# ddr32ss_EMIF_CTLCFG_0F308000h register map
Vendor: Texas Instruments
Registers are 32-bit, read-write, reset 0x0 unless marked. A register's access mark holds for its fields unless they carry their own. Offsets are as the file gives them; [hi:lo] are bit positions; lines under a group give offsets from that group; {n}, {i} and the like mark numbered series.

## emif_ctlcfg (part 7 of 13)
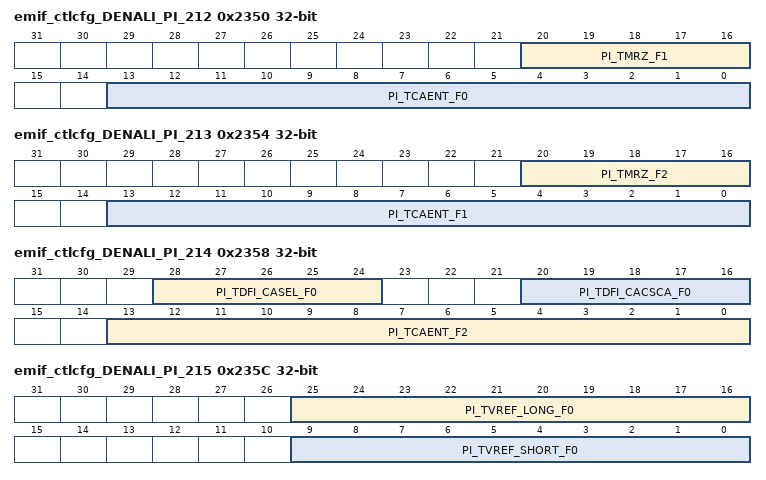
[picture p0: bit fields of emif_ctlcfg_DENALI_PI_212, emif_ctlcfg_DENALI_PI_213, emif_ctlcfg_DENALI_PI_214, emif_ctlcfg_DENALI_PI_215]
0x2350 emif_ctlcfg_DENALI_PI_212
  [20:16] PI_TMRZ_F1 — Defines the delay between a MRW CA exit command and the DQ tristate in memory clocks for frequency set 1. Reset Source: ctl_amod_g_rst_n
  [13:0] PI_TCAENT_F0 — Defines the DRAM tCAENT term, in memory clocks for frequency set 0. Reset Source: ctl_amod_g_rst_n
0x2354 emif_ctlcfg_DENALI_PI_213
  [20:16] PI_TMRZ_F2 — Defines the delay between a MRW CA exit command and the DQ tristate in memory clocks for frequency set 2. Reset Source: ctl_amod_g_rst_n
  [13:0] PI_TCAENT_F1 — Defines the DRAM tCAENT term, in memory clocks for frequency set 1. Reset Source: ctl_amod_g_rst_n
0x2358 emif_ctlcfg_DENALI_PI_214
  [28:24] PI_TDFI_CASEL_F0 — Defines the DFI tcalvl_ca_sel timing parameter, the width of dfi_calvl_ca_sel in PHY DFI clock cycles for frequency set 0. Reset Source: ctl_amod_g_rst_n
  [20:16] PI_TDFI_CACSCA_F0 — Defines the DFI tcalvl_cs_ca timing parameter, the number of PHY DFI clocks from the assertion of dfi_calvl_ca_sel to the assertion of dfi_cs for frequency set 0. Reset Source: ctl_amod_g_rst_n
  [13:0] PI_TCAENT_F2 — Defines the DRAM tCAENT term, in memory clocks for frequency set 2. Reset Source: ctl_amod_g_rst_n
0x235C emif_ctlcfg_DENALI_PI_215
  [25:16] PI_TVREF_LONG_F0 — Defines the delay in PI clock cycles between the dfi_calvl_strobe to the next command if the pi_calvl_vref_stepsize parameter gt 1 for frequency set 0. Reset Source: ctl_amod_g_rst_n
  [9:0] PI_TVREF_SHORT_F0 — Defines the delay in PI clock cycles between the dfi_calvl_strobe to the next command if the pi_calvl_vref_stepsize parameter = 1 for frequency set 0. Reset Source: ctl_amod_g_rst_n
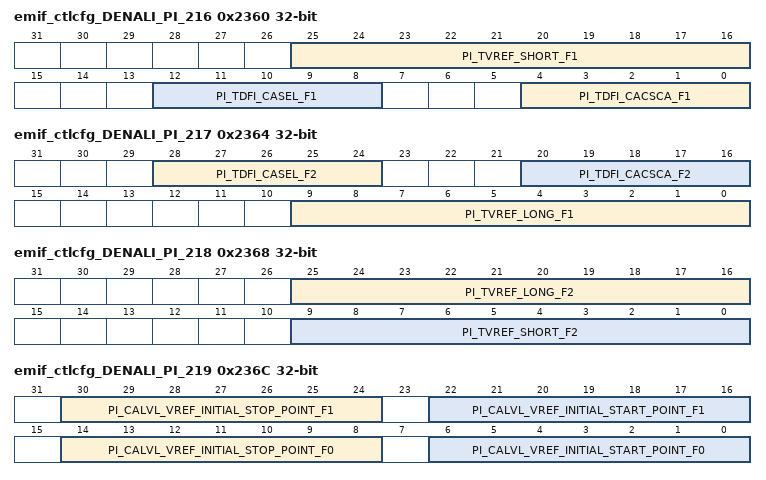
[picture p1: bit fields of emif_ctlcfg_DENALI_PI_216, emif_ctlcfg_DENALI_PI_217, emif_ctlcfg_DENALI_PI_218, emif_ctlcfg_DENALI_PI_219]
0x2360 emif_ctlcfg_DENALI_PI_216
  [25:16] PI_TVREF_SHORT_F1 — Defines the delay in PI clock cycles between the dfi_calvl_strobe to the next command if the pi_calvl_vref_stepsize parameter = 1 for frequency set 1. Reset Source: ctl_amod_g_rst_n
  [12:8] PI_TDFI_CASEL_F1 — Defines the DFI tcalvl_ca_sel timing parameter, the width of dfi_calvl_ca_sel in PHY DFI clock cycles for frequency set 1. Reset Source: ctl_amod_g_rst_n
  [4:0] PI_TDFI_CACSCA_F1 — Defines the DFI tcalvl_cs_ca timing parameter, the number of PHY DFI clocks from the assertion of dfi_calvl_ca_sel to the assertion of dfi_cs for frequency set 1. Reset Source: ctl_amod_g_rst_n
0x2364 emif_ctlcfg_DENALI_PI_217
  [28:24] PI_TDFI_CASEL_F2 — Defines the DFI tcalvl_ca_sel timing parameter, the width of dfi_calvl_ca_sel in PHY DFI clock cycles for frequency set 2. Reset Source: ctl_amod_g_rst_n
  [20:16] PI_TDFI_CACSCA_F2 — Defines the DFI tcalvl_cs_ca timing parameter, the number of PHY DFI clocks from the assertion of dfi_calvl_ca_sel to the assertion of dfi_cs for frequency set 2. Reset Source: ctl_amod_g_rst_n
  [9:0] PI_TVREF_LONG_F1 — Defines the delay in PI clock cycles between the dfi_calvl_strobe to the next command if the pi_calvl_vref_stepsize parameter gt 1 for frequency set 1. Reset Source: ctl_amod_g_rst_n
0x2368 emif_ctlcfg_DENALI_PI_218
  [25:16] PI_TVREF_LONG_F2 — Defines the delay in PI clock cycles between the dfi_calvl_strobe to the next command if the pi_calvl_vref_stepsize parameter gt 1 for frequency set 2. Reset Source: ctl_amod_g_rst_n
  [9:0] PI_TVREF_SHORT_F2 — Defines the delay in PI clock cycles between the dfi_calvl_strobe to the next command if the pi_calvl_vref_stepsize parameter = 1 for frequency set 2. Reset Source: ctl_amod_g_rst_n
0x236C emif_ctlcfg_DENALI_PI_219
  [30:24] PI_CALVL_VREF_INITIAL_STOP_POINT_F1 — The end point of initial training for the Vref[ca] training for frequency set 1 { vrefca_range, vref_ca_setting[5:0]}. Reset Source: ctl_amod_g_rst_n
  [22:16] PI_CALVL_VREF_INITIAL_START_POINT_F1 — The start point of initial training for the Vref[ca] training for frequency set 1 { vrefca_range, vref_ca_setting[5:0]}. Reset Source: ctl_amod_g_rst_n
  [14:8] PI_CALVL_VREF_INITIAL_STOP_POINT_F0 — The end point of initial training for the Vref[ca] training for frequency set 0 { vrefca_range, vref_ca_setting[5:0]}. Reset Source: ctl_amod_g_rst_n
  [6:0] PI_CALVL_VREF_INITIAL_START_POINT_F0 — The start point of initial training for the Vref[ca] training for frequency set 0 { vrefca_range, vref_ca_setting[5:0]}. Reset Source: ctl_amod_g_rst_n
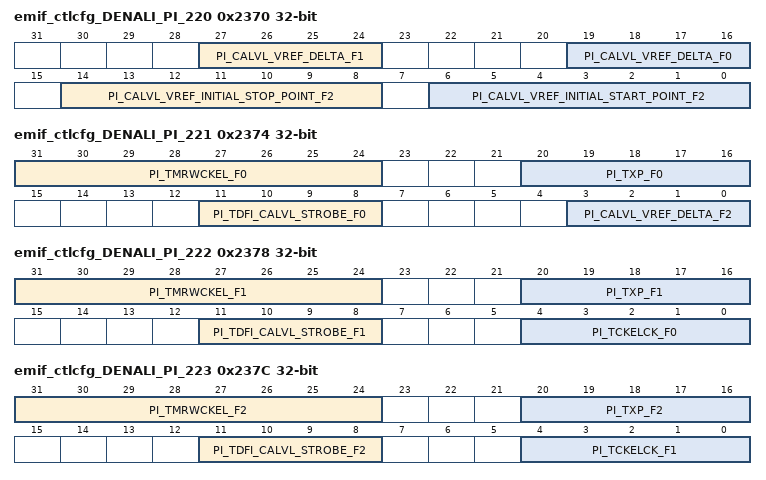
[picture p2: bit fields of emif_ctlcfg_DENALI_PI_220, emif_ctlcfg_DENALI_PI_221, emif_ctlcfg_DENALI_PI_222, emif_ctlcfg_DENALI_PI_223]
0x2370 emif_ctlcfg_DENALI_PI_220
  [27:24] PI_CALVL_VREF_DELTA_F1 — The delta fro the current CA vref for non-initial CA training for frequency set 1. Reset Source: ctl_amod_g_rst_n
  [19:16] PI_CALVL_VREF_DELTA_F0 — The delta fro the current CA vref for non-initial CA training for frequency set 0. Reset Source: ctl_amod_g_rst_n
  [14:8] PI_CALVL_VREF_INITIAL_STOP_POINT_F2 — The end point of initial training for the Vref[ca] training for frequency set 2 { vrefca_range, vref_ca_setting[5:0]}. Reset Source: ctl_amod_g_rst_n
  [6:0] PI_CALVL_VREF_INITIAL_START_POINT_F2 — The start point of initial training for the Vref[ca] training for frequency set 2 { vrefca_range, vref_ca_setting[5:0]}. Reset Source: ctl_amod_g_rst_n
0x2374 emif_ctlcfg_DENALI_PI_221
  [31:24] PI_TMRWCKEL_F0 — Valid Clock and CS Requirement before CKE deassert after MRW Command for frequency set 0. Reset Source: ctl_amod_g_rst_n
  [20:16] PI_TXP_F0 — CKE assert to next valid command delay for frequency set 0. Reset Source: ctl_amod_g_rst_n
  [11:8] PI_TDFI_CALVL_STROBE_F0 — Minimum number of DFI PHY clocks from dfi_calvl_data to dfi_calvl_strobe mode for frequency set 0. Reset Source: ctl_amod_g_rst_n
  [3:0] PI_CALVL_VREF_DELTA_F2 — The delta fro the current CA vref for non-initial CA training for frequency set 2. Reset Source: ctl_amod_g_rst_n
0x2378 emif_ctlcfg_DENALI_PI_222
  [31:24] PI_TMRWCKEL_F1 — Valid Clock and CS Requirement before CKE deassert after MRW Command for frequency set 1. Reset Source: ctl_amod_g_rst_n
  [20:16] PI_TXP_F1 — CKE assert to next valid command delay for frequency set 1. Reset Source: ctl_amod_g_rst_n
  [11:8] PI_TDFI_CALVL_STROBE_F1 — Minimum number of DFI PHY clocks from dfi_calvl_data to dfi_calvl_strobe mode for frequency set 1. Reset Source: ctl_amod_g_rst_n
  [4:0] PI_TCKELCK_F0 — Valid Clock Requirement after CKE deassert for frequency set 0. Reset Source: ctl_amod_g_rst_n
0x237C emif_ctlcfg_DENALI_PI_223
  [31:24] PI_TMRWCKEL_F2 — Valid Clock and CS Requirement before CKE deassert after MRW Command for frequency set 2. Reset Source: ctl_amod_g_rst_n
  [20:16] PI_TXP_F2 — CKE assert to next valid command delay for frequency set 2. Reset Source: ctl_amod_g_rst_n
  [11:8] PI_TDFI_CALVL_STROBE_F2 — Minimum number of DFI PHY clocks from dfi_calvl_data to dfi_calvl_strobe mode for frequency set 2. Reset Source: ctl_amod_g_rst_n
  [4:0] PI_TCKELCK_F1 — Valid Clock Requirement after CKE deassert for frequency set 1. Reset Source: ctl_amod_g_rst_n
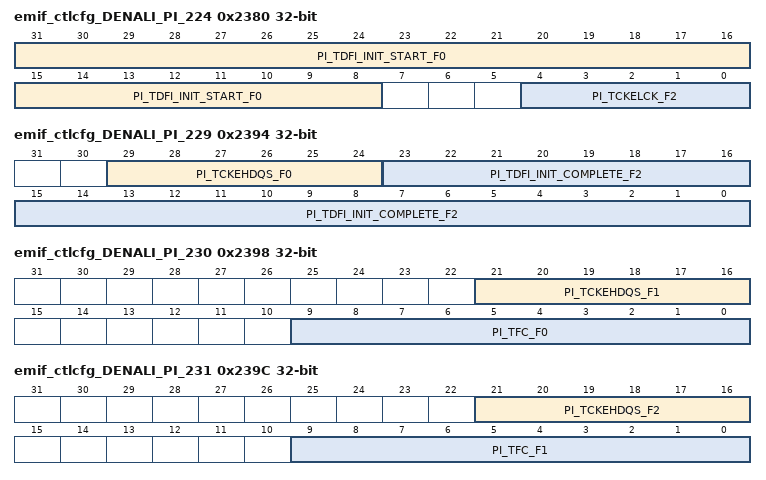
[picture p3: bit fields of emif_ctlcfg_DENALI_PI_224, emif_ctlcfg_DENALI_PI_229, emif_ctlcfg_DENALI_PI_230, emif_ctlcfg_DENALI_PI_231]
0x2380 emif_ctlcfg_DENALI_PI_224
  [31:8] PI_TDFI_INIT_START_F0 — Defines the DFI tINIT_START timing parameter [in DFI clocks] for frequency set 0, the maximum number of cycles between a dfi_init_start assertion and a dfi_init_complete de-assertion from the PHY. Reset Source: ctl_amod_g_rst_n
  [4:0] PI_TCKELCK_F2 — Valid Clock Requirement after CKE deassert for frequency set 2. Reset Source: ctl_amod_g_rst_n
0x2384 emif_ctlcfg_DENALI_PI_225
  [23:0] PI_TDFI_INIT_COMPLETE_F0 — Defines the DFI tINIT_COMPLETE timing parameter [in DFI clocks] for frequency set 0, the maximum cycles between a dfi_init_start de-assertion and a dfi_init_complete assertion from the PHY. Reset Source: ctl_amod_g_rst_n
0x2388 emif_ctlcfg_DENALI_PI_226
  [23:0] PI_TDFI_INIT_START_F1 — Defines the DFI tINIT_START timing parameter [in DFI clocks] for frequency set 1, the maximum number of cycles between a dfi_init_start assertion and a dfi_init_complete de-assertion from the PHY. Reset Source: ctl_amod_g_rst_n
0x238C emif_ctlcfg_DENALI_PI_227
  [23:0] PI_TDFI_INIT_COMPLETE_F1 — Defines the DFI tINIT_COMPLETE timing parameter [in DFI clocks] for frequency set 1, the maximum cycles between a dfi_init_start de-assertion and a dfi_init_complete assertion from the PHY. Reset Source: ctl_amod_g_rst_n
0x2390 emif_ctlcfg_DENALI_PI_228
  [23:0] PI_TDFI_INIT_START_F2 — Defines the DFI tINIT_START timing parameter [in DFI clocks] for frequency set 2, the maximum number of cycles between a dfi_init_start assertion and a dfi_init_complete de-assertion from the PHY. Reset Source: ctl_amod_g_rst_n
0x2394 emif_ctlcfg_DENALI_PI_229
  [29:24] PI_TCKEHDQS_F0 — The DRAM timing tCKEHDQS, minimum delay from CKE high to strobe high impedance for frequency set 0. Reset Source: ctl_amod_g_rst_n
  [23:0] PI_TDFI_INIT_COMPLETE_F2 — Defines the DFI tINIT_COMPLETE timing parameter [in DFI clocks] for frequency set 2, the maximum cycles between a dfi_init_start de-assertion and a dfi_init_complete assertion from the PHY. Reset Source: ctl_amod_g_rst_n
0x2398 emif_ctlcfg_DENALI_PI_230
  [21:16] PI_TCKEHDQS_F1 — The DRAM timing tCKEHDQS, minimum delay from CKE high to strobe high impedance for frequency set 1. Reset Source: ctl_amod_g_rst_n
  [9:0] PI_TFC_F0 — The delay in PHY clock cycles from setting MR13.OP7 to any valid command for frequency set 0. Reset Source: ctl_amod_g_rst_n
0x239C emif_ctlcfg_DENALI_PI_231
  [21:16] PI_TCKEHDQS_F2 — The DRAM timing tCKEHDQS, minimum delay from CKE high to strobe high impedance for frequency set 2. Reset Source: ctl_amod_g_rst_n
  [9:0] PI_TFC_F1 — The delay in PHY clock cycles from setting MR13.OP7 to any valid command for frequency set 1. Reset Source: ctl_amod_g_rst_n
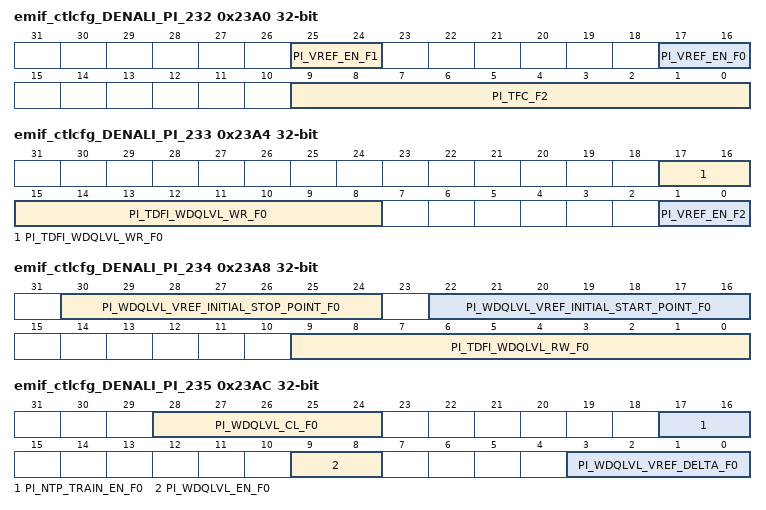
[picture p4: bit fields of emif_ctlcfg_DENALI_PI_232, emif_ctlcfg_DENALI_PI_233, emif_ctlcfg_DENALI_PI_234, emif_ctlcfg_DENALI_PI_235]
0x23A0 emif_ctlcfg_DENALI_PI_232
  [25:24] PI_VREF_EN_F1 — Enable VREF training during power-up initialization for frequency set 1. Bit[1] represents the support when non-initialization. Bit[0]represents the support when initialization. Set to 1 to enable. Reset Source: ctl_amod_g_rst_n
  [17:16] PI_VREF_EN_F0 — Enable VREF training during power-up initialization for frequency set 0. Bit[1] represents the support when non-initialization. Bit[0]represents the support when initialization. Set to 1 to enable. Reset Source: ctl_amod_g_rst_n
  [9:0] PI_TFC_F2 — The delay in PHY clock cycles from setting MR13.OP7 to any valid command for frequency set 2. Reset Source: ctl_amod_g_rst_n
0x23A4 emif_ctlcfg_DENALI_PI_233
  [17:8] PI_TDFI_WDQLVL_WR_F0 — Switch time from write to read for frequency set 0. Reset Source: ctl_amod_g_rst_n
  [1:0] PI_VREF_EN_F2 — Enable VREF training during power-up initialization for frequency set 2. Bit[1] represents the support when non-initialization. Bit[0]represents the support when initialization. Set to 1 to enable. Reset Source: ctl_amod_g_rst_n
0x23A8 emif_ctlcfg_DENALI_PI_234
  [30:24] PI_WDQLVL_VREF_INITIAL_STOP_POINT_F0 — Write DQ training vref initial training stop value for frequency set 0. Reset Source: ctl_amod_g_rst_n
  [22:16] PI_WDQLVL_VREF_INITIAL_START_POINT_F0 — Write DQ training vref initial training start value for frequency set 0. Reset Source: ctl_amod_g_rst_n
  [9:0] PI_TDFI_WDQLVL_RW_F0 — Switch time from read to write for frequency set 0. Reset Source: ctl_amod_g_rst_n
0x23AC emif_ctlcfg_DENALI_PI_235
  [28:24] PI_WDQLVL_CL_F0 — CL when the Read DBI disabled while doing WDQ training for frequency set 0. Reset Source: ctl_amod_g_rst_n
  [17:16] PI_NTP_TRAIN_EN_F0 — Indicates whether the no topology WDQ training is enabled. Bit[1] represents the support when non-initialization. Bit[0]represents the support when initialization. Reset Source: ctl_amod_g_rst_n
  [9:8] PI_WDQLVL_EN_F0 — Indicates if Write DQ leveling is enabled for frequency set 0. Bit[1] represents the support when non-initialization. Bit[0]represents the support when initialization. Reset Source: ctl_amod_g_rst_n
  [3:0] PI_WDQLVL_VREF_DELTA_F0 — The delta from the current Write DQ vref adjustment for non-initial wdq training for frequency set 0. Reset Source: ctl_amod_g_rst_n
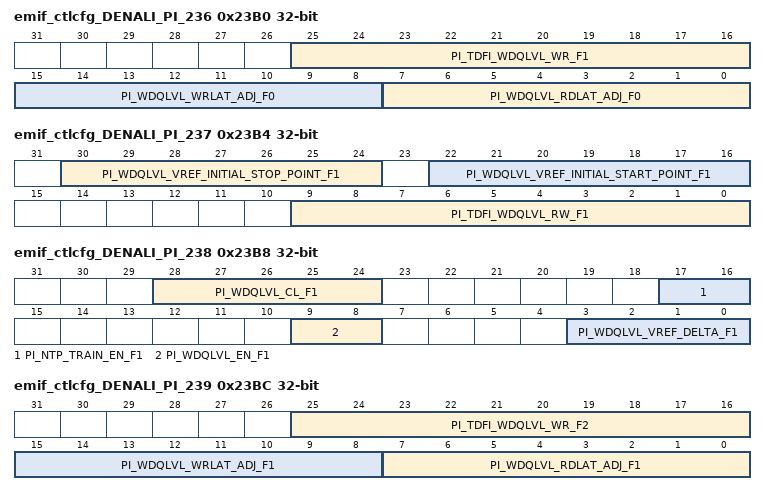
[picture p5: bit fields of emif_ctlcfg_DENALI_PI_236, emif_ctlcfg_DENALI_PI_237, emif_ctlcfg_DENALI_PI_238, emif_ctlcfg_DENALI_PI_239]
0x23B0 emif_ctlcfg_DENALI_PI_236
  [25:16] PI_TDFI_WDQLVL_WR_F1 — Switch time from write to read for frequency set 1. Reset Source: ctl_amod_g_rst_n
  [15:8] PI_WDQLVL_WRLAT_ADJ_F0 — Adjusted Tdfi_wrdata_en value for PHY read timing when read dbi disabled for frequency set 0, used for WDQ training. Reset Source: ctl_amod_g_rst_n
  [7:0] PI_WDQLVL_RDLAT_ADJ_F0 — Adjusted Tdfi_rddata_en value for PHY read timing when read dbi disabled for frequency set 0, used for WDQ training. Reset Source: ctl_amod_g_rst_n
0x23B4 emif_ctlcfg_DENALI_PI_237
  [30:24] PI_WDQLVL_VREF_INITIAL_STOP_POINT_F1 — Write DQ training vref initial training stop value for frequency set 1. Reset Source: ctl_amod_g_rst_n
  [22:16] PI_WDQLVL_VREF_INITIAL_START_POINT_F1 — Write DQ training vref initial training start value for frequency set 1. Reset Source: ctl_amod_g_rst_n
  [9:0] PI_TDFI_WDQLVL_RW_F1 — Switch time from read to write for frequency set 1. Reset Source: ctl_amod_g_rst_n
0x23B8 emif_ctlcfg_DENALI_PI_238
  [28:24] PI_WDQLVL_CL_F1 — CL when the Read DBI disabled while doing WDQ training for frequency set 1. Reset Source: ctl_amod_g_rst_n
  [17:16] PI_NTP_TRAIN_EN_F1 — Indicates whether the no topology WDQ training is enabled. Bit[1] represents the support when non-initialization. Bit[0]represents the support when initialization. Reset Source: ctl_amod_g_rst_n
  [9:8] PI_WDQLVL_EN_F1 — Indicates if Write DQ leveling is enabled for frequency set 1. Bit[1] represents the support when non-initialization. Bit[0]represents the support when initialization. Reset Source: ctl_amod_g_rst_n
  [3:0] PI_WDQLVL_VREF_DELTA_F1 — The delta from the current Write DQ vref adjustment for non-initial wdq training for frequency set 1. Reset Source: ctl_amod_g_rst_n
0x23BC emif_ctlcfg_DENALI_PI_239
  [25:16] PI_TDFI_WDQLVL_WR_F2 — Switch time from write to read for frequency set 2. Reset Source: ctl_amod_g_rst_n
  [15:8] PI_WDQLVL_WRLAT_ADJ_F1 — Adjusted Tdfi_wrdata_en value for PHY read timing when read dbi disabled for frequency set 1, used for WDQ training. Reset Source: ctl_amod_g_rst_n
  [7:0] PI_WDQLVL_RDLAT_ADJ_F1 — Adjusted Tdfi_rddata_en value for PHY read timing when read dbi disabled for frequency set 1, used for WDQ training. Reset Source: ctl_amod_g_rst_n
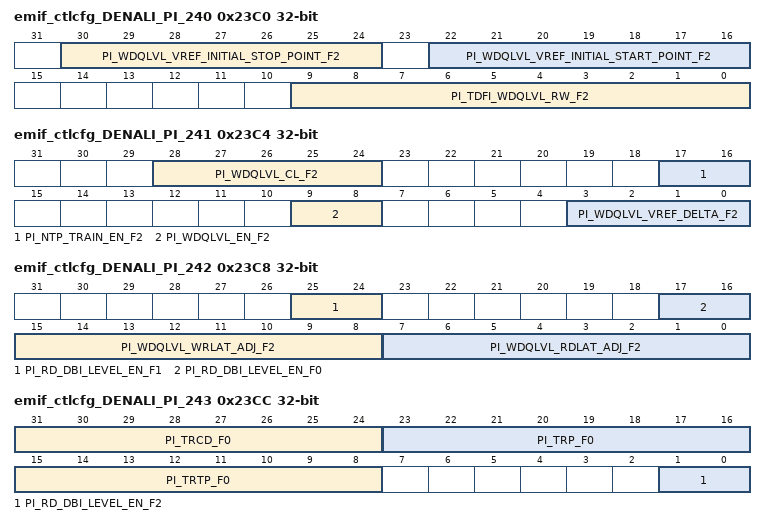
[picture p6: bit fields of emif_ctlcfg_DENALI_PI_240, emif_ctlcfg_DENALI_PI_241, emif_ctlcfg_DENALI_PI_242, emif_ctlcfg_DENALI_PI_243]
0x23C0 emif_ctlcfg_DENALI_PI_240
  [30:24] PI_WDQLVL_VREF_INITIAL_STOP_POINT_F2 — Write DQ training vref initial training stop value for frequency set 2. Reset Source: ctl_amod_g_rst_n
  [22:16] PI_WDQLVL_VREF_INITIAL_START_POINT_F2 — Write DQ training vref initial training start value for frequency set 2. Reset Source: ctl_amod_g_rst_n
  [9:0] PI_TDFI_WDQLVL_RW_F2 — Switch time from read to write for frequency set 2. Reset Source: ctl_amod_g_rst_n
0x23C4 emif_ctlcfg_DENALI_PI_241
  [28:24] PI_WDQLVL_CL_F2 — CL when the Read DBI disabled while doing WDQ training for frequency set 2. Reset Source: ctl_amod_g_rst_n
  [17:16] PI_NTP_TRAIN_EN_F2 — Indicates whether the no topology WDQ training is enabled. Bit[1] represents the support when non-initialization. Bit[0]represents the support when initialization. Reset Source: ctl_amod_g_rst_n
  [9:8] PI_WDQLVL_EN_F2 — Indicates if Write DQ leveling is enabled for frequency set 2. Bit[1] represents the support when non-initialization. Bit[0]represents the support when initialization. Reset Source: ctl_amod_g_rst_n
  [3:0] PI_WDQLVL_VREF_DELTA_F2 — The delta from the current Write DQ vref adjustment for non-initial wdq training for frequency set 2. Reset Source: ctl_amod_g_rst_n
0x23C8 emif_ctlcfg_DENALI_PI_242
  [25:24] PI_RD_DBI_LEVEL_EN_F1 — Read DBI leveling enable, only can be enabled when READ DBI supported for DDR4, and PI_WDQLVL_EN or PI_RDLVL_EN configured by 1 for frequency set 1. Bit[1] represents the support when non-initialization. Bit[0]represents the support when initialization. Reset Source: ctl_amod_g_rst_n
  [17:16] PI_RD_DBI_LEVEL_EN_F0 — Read DBI leveling enable, only can be enabled when READ DBI supported for DDR4, and PI_WDQLVL_EN or PI_RDLVL_EN configured by 1 for frequency set 0. Bit[1] represents the support when non-initialization. Bit[0]represents the support when initialization. Reset Source: ctl_amod_g_rst_n
  [15:8] PI_WDQLVL_WRLAT_ADJ_F2 — Adjusted Tdfi_wrdata_en value for PHY read timing when read dbi disabled for frequency set 2, used for WDQ training. Reset Source: ctl_amod_g_rst_n
  [7:0] PI_WDQLVL_RDLAT_ADJ_F2 — Adjusted Tdfi_rddata_en value for PHY read timing when read dbi disabled for frequency set 2, used for WDQ training. Reset Source: ctl_amod_g_rst_n
0x23CC emif_ctlcfg_DENALI_PI_243
  [31:24] PI_TRCD_F0 — DRAM tRCD value in cycles for frequency set 0. Reset Source: ctl_amod_g_rst_n
  [23:16] PI_TRP_F0 — DRAM tRP value in cycles for frequency set 0. Reset Source: ctl_amod_g_rst_n
  [15:8] PI_TRTP_F0 — DRAM tRTP value in cycles for frequency set 0. Reset Source: ctl_amod_g_rst_n
  [1:0] PI_RD_DBI_LEVEL_EN_F2 — Read DBI leveling enable, only can be enabled when READ DBI supported for DDR4, and PI_WDQLVL_EN or PI_RDLVL_EN configured by 1 for frequency set 2. Bit[1] represents the support when non-initialization. Bit[0]represents the support when initialization. Reset Source: ctl_amod_g_rst_n
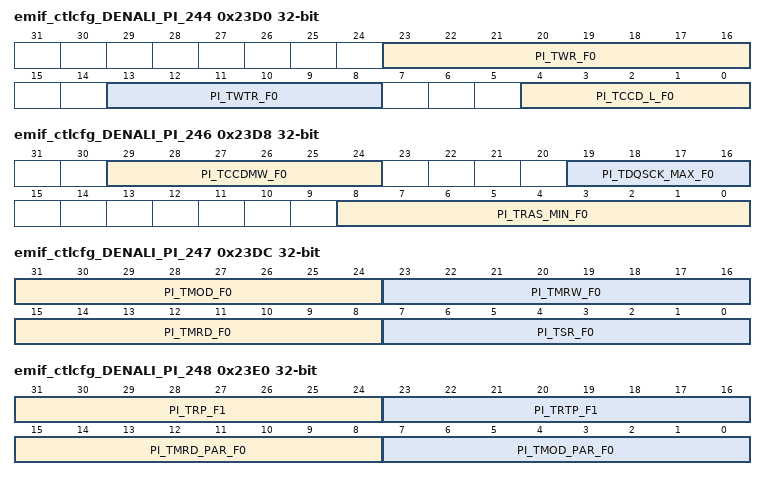
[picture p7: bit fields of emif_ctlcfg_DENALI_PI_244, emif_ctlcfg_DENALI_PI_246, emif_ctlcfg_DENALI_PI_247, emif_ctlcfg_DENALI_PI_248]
0x23D0 emif_ctlcfg_DENALI_PI_244
  [23:16] PI_TWR_F0 — DRAM tWR value in cycles for frequency set 0. Reset Source: ctl_amod_g_rst_n
  [13:8] PI_TWTR_F0 — DRAM tWTR value in cycles for frequency set 0. Reset Source: ctl_amod_g_rst_n
  [4:0] PI_TCCD_L_F0 — DRAM CAS-to_CAS value within the same bank group in cycles for frequency set 0. Reset Source: ctl_amod_g_rst_n
0x23D4 emif_ctlcfg_DENALI_PI_245
  [19:0] PI_TRAS_MAX_F0 — DRAM tRAS_MAX value in cycles for frequency set 0. Reset Source: ctl_amod_g_rst_n
0x23D8 emif_ctlcfg_DENALI_PI_246
  [29:24] PI_TCCDMW_F0 — LPDDR4 DRAM tCCDMW in cycles for frequency set 0. Reset Source: ctl_amod_g_rst_n
  [19:16] PI_TDQSCK_MAX_F0 — Additional delay needed for tDQSCK for frequency set 0. Reset Source: ctl_amod_g_rst_n
  [8:0] PI_TRAS_MIN_F0 — DRAM tRAS_MIN value in cycles for frequency set 0. Reset Source: ctl_amod_g_rst_n
0x23DC emif_ctlcfg_DENALI_PI_247
  [31:24] PI_TMOD_F0 — DRAM tMOD value in cycles for frequency set 0. Reset Source: ctl_amod_g_rst_n
  [23:16] PI_TMRW_F0 — DRAM tMRW value in cycles for frequency set 0. Reset Source: ctl_amod_g_rst_n
  [15:8] PI_TMRD_F0 — DRAM tMRD value in cycles for frequency set 0. Reset Source: ctl_amod_g_rst_n
  [7:0] PI_TSR_F0 — Min cycles from sref entry to sref exit for frequency set 0. Reset Source: ctl_amod_g_rst_n
0x23E0 emif_ctlcfg_DENALI_PI_248
  [31:24] PI_TRP_F1 — DRAM tRP value in cycles for frequency set 1. Reset Source: ctl_amod_g_rst_n
  [23:16] PI_TRTP_F1 — DRAM tRTP value in cycles for frequency set 1. Reset Source: ctl_amod_g_rst_n
  [15:8] PI_TMRD_PAR_F0 — DRAM tMRD value when CA parity is enabled in cycles for frequency set 0. Reset Source: ctl_amod_g_rst_n
  [7:0] PI_TMOD_PAR_F0 — DRAM tMOD value when CA parity is enabled in cycles for frequency set 0. Reset Source: ctl_amod_g_rst_n
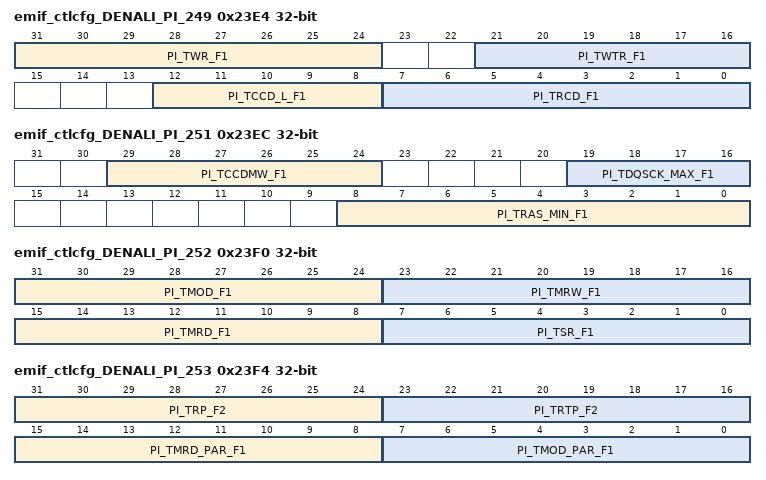
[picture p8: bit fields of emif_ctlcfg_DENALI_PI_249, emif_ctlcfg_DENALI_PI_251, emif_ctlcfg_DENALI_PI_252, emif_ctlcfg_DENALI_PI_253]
0x23E4 emif_ctlcfg_DENALI_PI_249
  [31:24] PI_TWR_F1 — DRAM tWR value in cycles for frequency set 1. Reset Source: ctl_amod_g_rst_n
  [21:16] PI_TWTR_F1 — DRAM tWTR value in cycles for frequency set 1. Reset Source: ctl_amod_g_rst_n
  [12:8] PI_TCCD_L_F1 — DRAM CAS-to_CAS value within the same bank group in cycles for frequency set 1. Reset Source: ctl_amod_g_rst_n
  [7:0] PI_TRCD_F1 — DRAM tRCD value in cycles for frequency set 1. Reset Source: ctl_amod_g_rst_n
0x23E8 emif_ctlcfg_DENALI_PI_250
  [19:0] PI_TRAS_MAX_F1 — DRAM tRAS_MAX value in cycles for frequency set 1. Reset Source: ctl_amod_g_rst_n
0x23EC emif_ctlcfg_DENALI_PI_251
  [29:24] PI_TCCDMW_F1 — LPDDR4 DRAM tCCDMW in cycles for frequency set 1. Reset Source: ctl_amod_g_rst_n
  [19:16] PI_TDQSCK_MAX_F1 — Additional delay needed for tDQSCK for frequency set 1. Reset Source: ctl_amod_g_rst_n
  [8:0] PI_TRAS_MIN_F1 — DRAM tRAS_MIN value in cycles for frequency set 1. Reset Source: ctl_amod_g_rst_n
0x23F0 emif_ctlcfg_DENALI_PI_252
  [31:24] PI_TMOD_F1 — DRAM tMOD value in cycles for frequency set 1. Reset Source: ctl_amod_g_rst_n
  [23:16] PI_TMRW_F1 — DRAM tMRW value in cycles for frequency set 1. Reset Source: ctl_amod_g_rst_n
  [15:8] PI_TMRD_F1 — DRAM tMRD value in cycles for frequency set 1. Reset Source: ctl_amod_g_rst_n
  [7:0] PI_TSR_F1 — Min cycles from sref entry to sref exit for frequency set 1. Reset Source: ctl_amod_g_rst_n
0x23F4 emif_ctlcfg_DENALI_PI_253
  [31:24] PI_TRP_F2 — DRAM tRP value in cycles for frequency set 2. Reset Source: ctl_amod_g_rst_n
  [23:16] PI_TRTP_F2 — DRAM tRTP value in cycles for frequency set 2. Reset Source: ctl_amod_g_rst_n
  [15:8] PI_TMRD_PAR_F1 — DRAM tMRD value when CA parity is enabled in cycles for frequency set 1. Reset Source: ctl_amod_g_rst_n
  [7:0] PI_TMOD_PAR_F1 — DRAM tMOD value when CA parity is enabled in cycles for frequency set 1. Reset Source: ctl_amod_g_rst_n
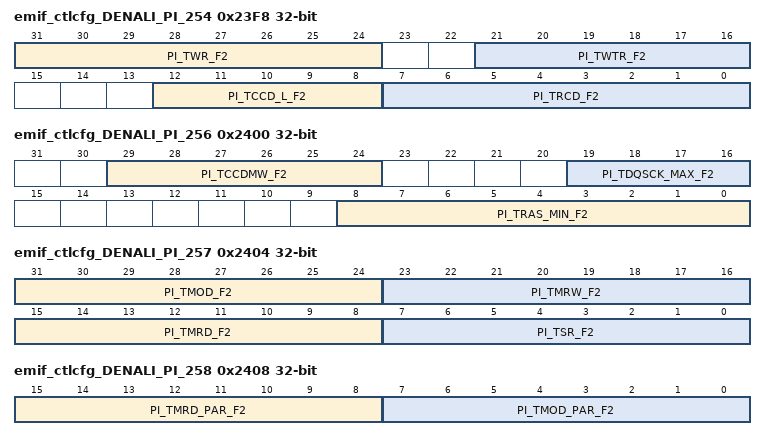
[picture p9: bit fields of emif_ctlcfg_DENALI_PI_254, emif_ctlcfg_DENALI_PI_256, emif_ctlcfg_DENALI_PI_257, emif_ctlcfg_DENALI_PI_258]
0x23F8 emif_ctlcfg_DENALI_PI_254
  [31:24] PI_TWR_F2 — DRAM tWR value in cycles for frequency set 2. Reset Source: ctl_amod_g_rst_n
  [21:16] PI_TWTR_F2 — DRAM tWTR value in cycles for frequency set 2. Reset Source: ctl_amod_g_rst_n
  [12:8] PI_TCCD_L_F2 — DRAM CAS-to_CAS value within the same bank group in cycles for frequency set 2. Reset Source: ctl_amod_g_rst_n
  [7:0] PI_TRCD_F2 — DRAM tRCD value in cycles for frequency set 2. Reset Source: ctl_amod_g_rst_n
0x23FC emif_ctlcfg_DENALI_PI_255
  [19:0] PI_TRAS_MAX_F2 — DRAM tRAS_MAX value in cycles for frequency set 2. Reset Source: ctl_amod_g_rst_n
0x2400 emif_ctlcfg_DENALI_PI_256
  [29:24] PI_TCCDMW_F2 — LPDDR4 DRAM tCCDMW in cycles for frequency set 2. Reset Source: ctl_amod_g_rst_n
  [19:16] PI_TDQSCK_MAX_F2 — Additional delay needed for tDQSCK for frequency set 2. Reset Source: ctl_amod_g_rst_n
  [8:0] PI_TRAS_MIN_F2 — DRAM tRAS_MIN value in cycles for frequency set 2. Reset Source: ctl_amod_g_rst_n
0x2404 emif_ctlcfg_DENALI_PI_257
  [31:24] PI_TMOD_F2 — DRAM tMOD value in cycles for frequency set 2. Reset Source: ctl_amod_g_rst_n
  [23:16] PI_TMRW_F2 — DRAM tMRW value in cycles for frequency set 2. Reset Source: ctl_amod_g_rst_n
  [15:8] PI_TMRD_F2 — DRAM tMRD value in cycles for frequency set 2. Reset Source: ctl_amod_g_rst_n
  [7:0] PI_TSR_F2 — Min cycles from sref entry to sref exit for frequency set 2. Reset Source: ctl_amod_g_rst_n
0x2408 emif_ctlcfg_DENALI_PI_258
  [15:8] PI_TMRD_PAR_F2 — DRAM tMRD value when CA parity is enabled in cycles for frequency set 2. Reset Source: ctl_amod_g_rst_n
  [7:0] PI_TMOD_PAR_F2 — DRAM tMOD value when CA parity is enabled in cycles for frequency set 2. Reset Source: ctl_amod_g_rst_n
0x240C emif_ctlcfg_DENALI_PI_259
  [20:0] PI_TDFI_CTRLUPD_MAX_F0 — Defines the DFI tCTRLUPD_MAX timing parameter [in DFI clocks] for frequency set 0, the maximum cycles that dfi_ctrlupd_req can be asserted. If programmed to a non-zero, a timing violation will cause an interrupt and bit [1] set in the PI_UPDATE_ERROR_STATUS parameter. Reset Source: ctl_amod_g_rst_n
0x2410 emif_ctlcfg_DENALI_PI_260
  [31:0] PI_TDFI_CTRLUPD_INTERVAL_F0 — Defines the DFI tCTRLUPD_INTERVAL timing parameter [in DFI clocks] for frequency set 0, the maximum cycles between dfi_ctrlupd_req assertions. If programmed to a non-zero, a timing violation will cause an interrupt and bit [0] set in the PI_UPDATE_ERROR_STATUS parameter. Reset Source: ctl_amod_g_rst_n
0x2414 emif_ctlcfg_DENALI_PI_261
  [20:0] PI_TDFI_CTRLUPD_MAX_F1 — Defines the DFI tCTRLUPD_MAX timing parameter [in DFI clocks] for frequency set 1, the maximum cycles that dfi_ctrlupd_req can be asserted. If programmed to a non-zero, a timing violation will cause an interrupt and bit [1] set in the PI_UPDATE_ERROR_STATUS parameter. Reset Source: ctl_amod_g_rst_n
0x2418 emif_ctlcfg_DENALI_PI_262
  [31:0] PI_TDFI_CTRLUPD_INTERVAL_F1 — Defines the DFI tCTRLUPD_INTERVAL timing parameter [in DFI clocks] for frequency set 1, the maximum cycles between dfi_ctrlupd_req assertions. If programmed to a non-zero, a timing violation will cause an interrupt and bit [0] set in the PI_UPDATE_ERROR_STATUS parameter. Reset Source: ctl_amod_g_rst_n
0x241C emif_ctlcfg_DENALI_PI_263
  [20:0] PI_TDFI_CTRLUPD_MAX_F2 — Defines the DFI tCTRLUPD_MAX timing parameter [in DFI clocks] for frequency set 2, the maximum cycles that dfi_ctrlupd_req can be asserted. If programmed to a non-zero, a timing violation will cause an interrupt and bit [1] set in the PI_UPDATE_ERROR_STATUS parameter. Reset Source: ctl_amod_g_rst_n
0x2420 emif_ctlcfg_DENALI_PI_264
  [31:0] PI_TDFI_CTRLUPD_INTERVAL_F2 — Defines the DFI tCTRLUPD_INTERVAL timing parameter [in DFI clocks] for frequency set 2, the maximum cycles between dfi_ctrlupd_req assertions. If programmed to a non-zero, a timing violation will cause an interrupt and bit [0] set in the PI_UPDATE_ERROR_STATUS parameter. Reset Source: ctl_amod_g_rst_n
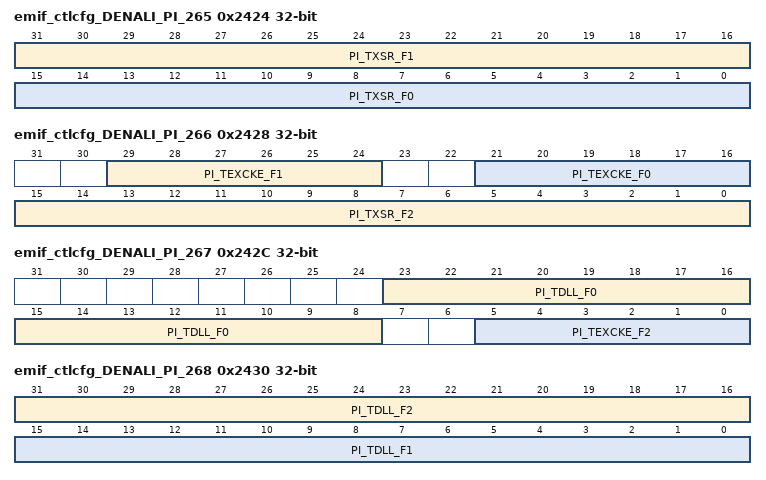
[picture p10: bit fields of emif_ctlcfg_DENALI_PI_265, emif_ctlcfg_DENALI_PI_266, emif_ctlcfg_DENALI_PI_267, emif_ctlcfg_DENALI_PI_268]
0x2424 emif_ctlcfg_DENALI_PI_265
  [31:16] PI_TXSR_F1 — DRAM TXSR value for frequency set 1 in cycles. Reset Source: ctl_amod_g_rst_n
  [15:0] PI_TXSR_F0 — DRAM TXSR value for frequency set 0 in cycles. Reset Source: ctl_amod_g_rst_n
0x2428 emif_ctlcfg_DENALI_PI_266
  [29:24] PI_TEXCKE_F1 — DRAM CKE low after SREF command timing for frequency set 1. Reset Source: ctl_amod_g_rst_n
  [21:16] PI_TEXCKE_F0 — DRAM CKE low after SREF command timing for frequency set 0. Reset Source: ctl_amod_g_rst_n
  [15:0] PI_TXSR_F2 — DRAM TXSR value for frequency set 2 in cycles. Reset Source: ctl_amod_g_rst_n
0x242C emif_ctlcfg_DENALI_PI_267
  [23:8] PI_TDLL_F0 — DRAM tDLL value for frequency set 0 in cycles. Reset Source: ctl_amod_g_rst_n
  [5:0] PI_TEXCKE_F2 — DRAM CKE low after SREF command timing for frequency set 2. Reset Source: ctl_amod_g_rst_n
0x2430 emif_ctlcfg_DENALI_PI_268
  [31:16] PI_TDLL_F2 — DRAM tDLL value for frequency set 2 in cycles. Reset Source: ctl_amod_g_rst_n
  [15:0] PI_TDLL_F1 — DRAM tDLL value for frequency set 1 in cycles. Reset Source: ctl_amod_g_rst_n
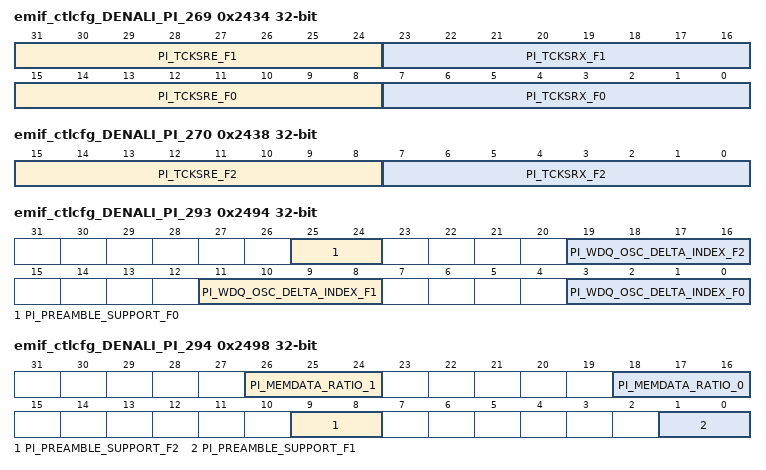
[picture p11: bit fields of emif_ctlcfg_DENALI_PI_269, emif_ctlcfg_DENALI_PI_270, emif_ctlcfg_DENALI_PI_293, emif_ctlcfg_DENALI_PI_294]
0x2434 emif_ctlcfg_DENALI_PI_269
  [31:24] PI_TCKSRE_F1 — DRAM tCKSRE value. Reset Source: ctl_amod_g_rst_n
  [23:16] PI_TCKSRX_F1 — DRAM tCKSRX value. Reset Source: ctl_amod_g_rst_n
  [15:8] PI_TCKSRE_F0 — DRAM tCKSRE value. Reset Source: ctl_amod_g_rst_n
  [7:0] PI_TCKSRX_F0 — DRAM tCKSRX value. Reset Source: ctl_amod_g_rst_n
0x2438 emif_ctlcfg_DENALI_PI_270
  [15:8] PI_TCKSRE_F2 — DRAM tCKSRE value. Reset Source: ctl_amod_g_rst_n
  [7:0] PI_TCKSRX_F2 — DRAM tCKSRX value. Reset Source: ctl_amod_g_rst_n
0x243C emif_ctlcfg_DENALI_PI_271
  [23:0] PI_TINIT_F0 — DRAM tINIT value for frequency set 0 in cycles. Reset Source: ctl_amod_g_rst_n
{0x2000+4i} emif_ctlcfg_DENALI_PI_{i} (i=272..274)
  [23:0] PI_TINIT{i-269}_F0 — DRAM tINIT{i-269} value for frequency set 0 in cycles. Reset Source: ctl_amod_g_rst_n
0x244C emif_ctlcfg_DENALI_PI_275
  [15:0] PI_TXSNR_F0 — DRAM tXSNR value for frequency set 0 in cycles. Reset Source: ctl_amod_g_rst_n
0x2450 emif_ctlcfg_DENALI_PI_276
  [23:0] PI_TINIT_F1 — DRAM tINIT value for frequency set 1 in cycles. Reset Source: ctl_amod_g_rst_n
{0x2000+4i} emif_ctlcfg_DENALI_PI_{i} (i=277..279)
  [23:0] PI_TINIT{i-274}_F1 — DRAM tINIT{i-274} value for frequency set 1 in cycles. Reset Source: ctl_amod_g_rst_n
0x2460 emif_ctlcfg_DENALI_PI_280
  [15:0] PI_TXSNR_F1 — DRAM tXSNR value for frequency set 1 in cycles. Reset Source: ctl_amod_g_rst_n
0x2464 emif_ctlcfg_DENALI_PI_281
  [23:0] PI_TINIT_F2 — DRAM tINIT value for frequency set 2 in cycles. Reset Source: ctl_amod_g_rst_n
{0x2000+4i} emif_ctlcfg_DENALI_PI_{i} (i=282..284)
  [23:0] PI_TINIT{i-279}_F2 — DRAM tINIT{i-279} value for frequency set 2 in cycles. Reset Source: ctl_amod_g_rst_n
0x2474 emif_ctlcfg_DENALI_PI_285
  [15:0] PI_TXSNR_F2 — DRAM tXSNR value for frequency set 2 in cycles. Reset Source: ctl_amod_g_rst_n
0x2478 emif_ctlcfg_DENALI_PI_286
  [27:16] PI_TZQCAL_F0 — Holds the DRAM ZQCAL value for frequency set 0 in cycles. Reset Source: ctl_amod_g_rst_n
0x247C emif_ctlcfg_DENALI_PI_287
  [6:0] PI_TZQLAT_F0 — Holds the DRAM ZQLAT value for frequency set 0 in cycles. Reset Source: ctl_amod_g_rst_n
0x2480 emif_ctlcfg_DENALI_PI_288
  [27:16] PI_TZQCAL_F1 — Holds the DRAM ZQCAL value for frequency set 1 in cycles. Reset Source: ctl_amod_g_rst_n
0x2484 emif_ctlcfg_DENALI_PI_289
  [6:0] PI_TZQLAT_F1 — Holds the DRAM ZQLAT value for frequency set 1 in cycles. Reset Source: ctl_amod_g_rst_n
0x2488 emif_ctlcfg_DENALI_PI_290
  [27:16] PI_TZQCAL_F2 — Holds the DRAM ZQCAL value for frequency set 2 in cycles. Reset Source: ctl_amod_g_rst_n
0x248C emif_ctlcfg_DENALI_PI_291
  [6:0] PI_TZQLAT_F2 — Holds the DRAM ZQLAT value for frequency set 2 in cycles. Reset Source: ctl_amod_g_rst_n
0x2490 emif_ctlcfg_DENALI_PI_292 access not given reset not defined
0x2494 emif_ctlcfg_DENALI_PI_293
  [25:24] PI_PREAMBLE_SUPPORT_F0 — bit0: Selection of one or two cycle preamble for read burst transfers. bit1: Selection of one or two cycles write burst transfers for NON-DDR5,one or multi[up to four] cycles write burst transfers for DDR5. Reset Source: ctl_amod_g_rst_n
  [19:16] PI_WDQ_OSC_DELTA_INDEX_F2 — WDQ DQS delay delta index for OSC triggered periodic training for frequency set 2. If the value is n, the delay is 2^n/512 cycle. Reset Source: ctl_amod_g_rst_n
  [11:8] PI_WDQ_OSC_DELTA_INDEX_F1 — WDQ DQS delay delta index for OSC triggered periodic training for frequency set 1. If the value is n, the delay is 2^n/512 cycle. Reset Source: ctl_amod_g_rst_n
  [3:0] PI_WDQ_OSC_DELTA_INDEX_F0 — WDQ DQS delay delta index for OSC triggered periodic training for frequency set 0. If the value is n, the delay is 2^n/512 cycle. Reset Source: ctl_amod_g_rst_n
0x2498 emif_ctlcfg_DENALI_PI_294
  [26:24] PI_MEMDATA_RATIO_1 — Defines the ratio of the DRAM device size on chip select 1 to the memory data width. Program with the log2 ratio of the memory data width to the device data width. Reset Source: ctl_amod_g_rst_n
  [18:16] PI_MEMDATA_RATIO_0 — Defines the ratio of the DRAM device size on chip select 0 to the memory data width. Program with the log2 ratio of the memory data width to the device data width. Reset Source: ctl_amod_g_rst_n
  [9:8] PI_PREAMBLE_SUPPORT_F2 — bit0: Selection of one or two cycle preamble for read burst transfers. bit1: Selection of one or two cycles write burst transfers for NON-DDR5,one or multi[up to four] cycles write burst transfers for DDR5. Reset Source: ctl_amod_g_rst_n
  [1:0] PI_PREAMBLE_SUPPORT_F1 — bit0: Selection of one or two cycle preamble for read burst transfers. bit1: Selection of one or two cycles write burst transfers for NON-DDR5,one or multi[up to four] cycles write burst transfers for DDR5. Reset Source: ctl_amod_g_rst_n
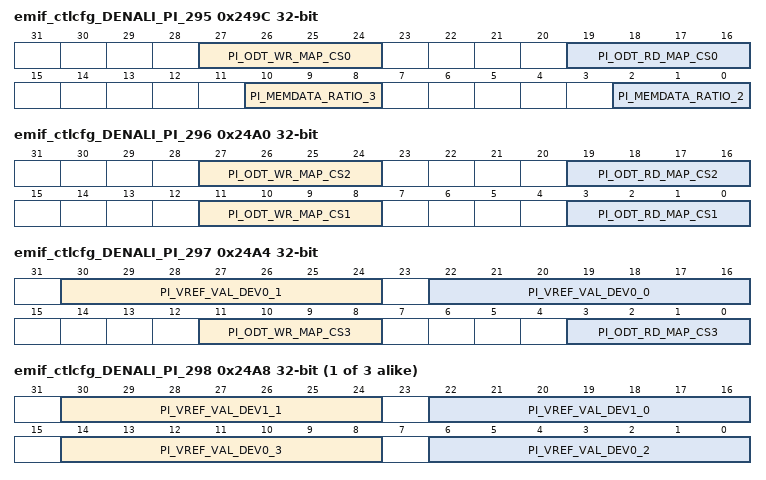
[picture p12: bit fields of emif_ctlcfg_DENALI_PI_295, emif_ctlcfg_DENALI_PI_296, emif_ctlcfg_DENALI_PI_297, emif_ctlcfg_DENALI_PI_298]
0x249C emif_ctlcfg_DENALI_PI_295
  [27:24] PI_ODT_WR_MAP_CS0 — Determines which chip[s] will have termination when a write occurs on chip select 0. Set bit X to enable termination on csX when cs0 is performing a write. Reset Source: ctl_amod_g_rst_n
  [19:16] PI_ODT_RD_MAP_CS0 — Determines which chip[s] will have termination when a read occurs on chip select 0. Set bit X to enable termination on csX when cs0 is performing a read. Reset Source: ctl_amod_g_rst_n
  [10:8] PI_MEMDATA_RATIO_3 — Defines the ratio of the DRAM device size on chip select 3 to the memory data width. Program with the log2 ratio of the memory data width to the device data width. Reset Source: ctl_amod_g_rst_n
  [2:0] PI_MEMDATA_RATIO_2 — Defines the ratio of the DRAM device size on chip select 2 to the memory data width. Program with the log2 ratio of the memory data width to the device data width. Reset Source: ctl_amod_g_rst_n
0x24A0 emif_ctlcfg_DENALI_PI_296
  [27:24] PI_ODT_WR_MAP_CS2 — Determines which chip[s] will have termination when a write occurs on chip select 2. Set bit X to enable termination on csX when cs2 is performing a write. Reset Source: ctl_amod_g_rst_n
  [19:16] PI_ODT_RD_MAP_CS2 — Determines which chip[s] will have termination when a read occurs on chip select 2. Set bit X to enable termination on csX when cs2 is performing a read. Reset Source: ctl_amod_g_rst_n
  [11:8] PI_ODT_WR_MAP_CS1 — Determines which chip[s] will have termination when a write occurs on chip select 1. Set bit X to enable termination on csX when cs1 is performing a write. Reset Source: ctl_amod_g_rst_n
  [3:0] PI_ODT_RD_MAP_CS1 — Determines which chip[s] will have termination when a read occurs on chip select 1. Set bit X to enable termination on csX when cs1 is performing a read. Reset Source: ctl_amod_g_rst_n
0x24A4 emif_ctlcfg_DENALI_PI_297
  [30:24] PI_VREF_VAL_DEV0_1 — Defines the range and value for VREF training for DRAM 0 for CS 1. If the PI_VREF_PDA_EN parameter is not set, device 0 values are used for all devices. Reset Source: ctl_amod_g_rst_n
  [22:16] PI_VREF_VAL_DEV0_0 — Defines the range and value for VREF training for DRAM 0 for CS 0. If the PI_VREF_PDA_EN parameter is not set, device 0 values are used for all devices. Reset Source: ctl_amod_g_rst_n
  [11:8] PI_ODT_WR_MAP_CS3 — Determines which chip[s] will have termination when a write occurs on chip select 3. Set bit X to enable termination on csX when cs3 is performing a write. Reset Source: ctl_amod_g_rst_n
  [3:0] PI_ODT_RD_MAP_CS3 — Determines which chip[s] will have termination when a read occurs on chip select 3. Set bit X to enable termination on csX when cs3 is performing a read. Reset Source: ctl_amod_g_rst_n
{0x2000+4i} emif_ctlcfg_DENALI_PI_{i} (i=298..300)
  [30:24] PI_VREF_VAL_DEV{i-297}_1 — Defines the range and value for VREF training for DRAM {i-297} for CS 1. If the PI_VREF_PDA_EN parameter is not set, device 0 values are used for all devices. Reset Source: ctl_amod_g_rst_n
  [22:16] PI_VREF_VAL_DEV{i-297}_0 — Defines the range and value for VREF training for DRAM {i-297} for CS 0. If the PI_VREF_PDA_EN parameter is not set, device 0 values are used for all devices. Reset Source: ctl_amod_g_rst_n
  [14:8] PI_VREF_VAL_DEV{i-298}_3 — Defines the range and value for VREF training for DRAM {i-298} for CS 3. If the PI_VREF_PDA_EN parameter is not set, device 0 values are used for all devices. Reset Source: ctl_amod_g_rst_n
  [6:0] PI_VREF_VAL_DEV{i-298}_2 — Defines the range and value for VREF training for DRAM {i-298} for CS 2. If the PI_VREF_PDA_EN parameter is not set, device 0 values are used for all devices. Reset Source: ctl_amod_g_rst_n
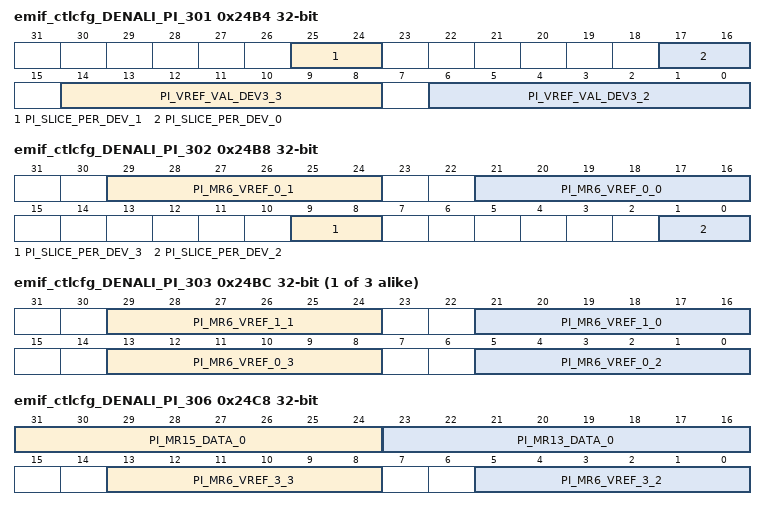
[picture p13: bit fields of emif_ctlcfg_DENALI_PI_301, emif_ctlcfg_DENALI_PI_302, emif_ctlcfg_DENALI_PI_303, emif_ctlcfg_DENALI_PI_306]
0x24B4 emif_ctlcfg_DENALI_PI_301
  [25:24] PI_SLICE_PER_DEV_1 — Indicates the number of data slices per memory device. The device width divided by 8. Reset Source: ctl_amod_g_rst_n
  [17:16] PI_SLICE_PER_DEV_0 — Indicates the number of data slices per memory device. The device width divided by 8. Reset Source: ctl_amod_g_rst_n
  [14:8] PI_VREF_VAL_DEV3_3 — Defines the range and value for VREF training for DRAM 3 for CS 3. If the PI_VREF_PDA_EN parameter is not set, device 0 values are used for all devices. Reset Source: ctl_amod_g_rst_n
  [6:0] PI_VREF_VAL_DEV3_2 — Defines the range and value for VREF training for DRAM 3 for CS 2. If the PI_VREF_PDA_EN parameter is not set, device 0 values are used for all devices. Reset Source: ctl_amod_g_rst_n
0x24B8 emif_ctlcfg_DENALI_PI_302 access per field
  [29:24] PI_MR6_VREF_0_1 ro — The parameter stores the vref value of every devices of the same CS. It is updated after WDQLVL PDA mode completed. READ-ONLY. Reset Source: ctl_amod_g_rst_n
  [21:16] PI_MR6_VREF_0_0 ro — The parameter stores the vref value of every devices of the same CS. It is updated after WDQLVL PDA mode completed. READ-ONLY. Reset Source: ctl_amod_g_rst_n
  [9:8] PI_SLICE_PER_DEV_3 rw — Indicates the number of data slices per memory device. The device width divided by 8. Reset Source: ctl_amod_g_rst_n
  [1:0] PI_SLICE_PER_DEV_2 rw — Indicates the number of data slices per memory device. The device width divided by 8. Reset Source: ctl_amod_g_rst_n
{0x2000+4i} emif_ctlcfg_DENALI_PI_{i} ro (i=303..305)
  [29:24] PI_MR6_VREF_{i-302}_1 — The parameter stores the vref value of every devices of the same CS. It is updated after WDQLVL PDA mode completed. READ-ONLY. Reset Source: ctl_amod_g_rst_n
  [21:16] PI_MR6_VREF_{i-302}_0 — The parameter stores the vref value of every devices of the same CS. It is updated after WDQLVL PDA mode completed. READ-ONLY. Reset Source: ctl_amod_g_rst_n
  [13:8] PI_MR6_VREF_{i-303}_3 — The parameter stores the vref value of every devices of the same CS. It is updated after WDQLVL PDA mode completed. READ-ONLY. Reset Source: ctl_amod_g_rst_n
  [5:0] PI_MR6_VREF_{i-303}_2 — The parameter stores the vref value of every devices of the same CS. It is updated after WDQLVL PDA mode completed. READ-ONLY. Reset Source: ctl_amod_g_rst_n
0x24C8 emif_ctlcfg_DENALI_PI_306 access per field
  [31:24] PI_MR15_DATA_0 rw — Data to program into memory mode register 15 for chip select 0. Reset Source: ctl_amod_g_rst_n
  [23:16] PI_MR13_DATA_0 rw — Data to program into memory mode register 13 for chip select 0. Reset Source: ctl_amod_g_rst_n
  [13:8] PI_MR6_VREF_3_3 ro — The parameter stores the vref value of every devices of the same CS. It is updated after WDQLVL PDA mode completed. READ-ONLY. Reset Source: ctl_amod_g_rst_n
  [5:0] PI_MR6_VREF_3_2 ro — The parameter stores the vref value of every devices of the same CS. It is updated after WDQLVL PDA mode completed. READ-ONLY. Reset Source: ctl_amod_g_rst_n
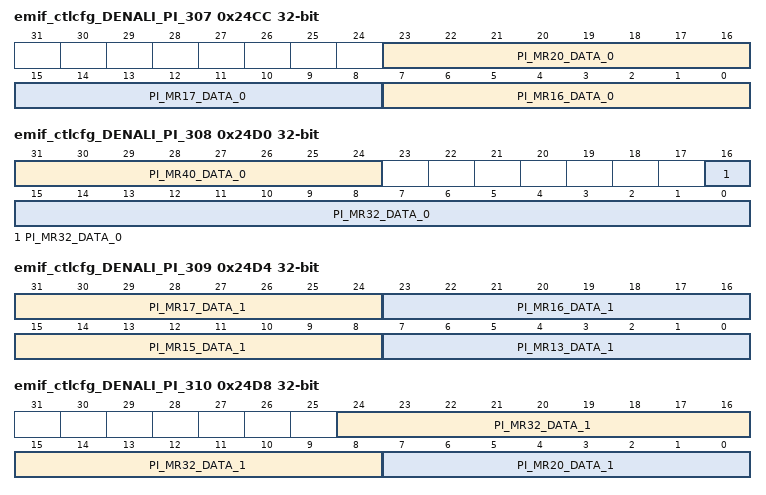
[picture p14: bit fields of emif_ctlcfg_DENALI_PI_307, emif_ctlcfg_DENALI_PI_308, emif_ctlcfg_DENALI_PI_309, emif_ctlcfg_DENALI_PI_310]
0x24CC emif_ctlcfg_DENALI_PI_307
  [23:16] PI_MR20_DATA_0 — Data to program into memory mode register 20 for chip select 0. Reset Source: ctl_amod_g_rst_n
  [15:8] PI_MR17_DATA_0 — Data to program into memory mode register 17 for chip select 0. Reset Source: ctl_amod_g_rst_n
  [7:0] PI_MR16_DATA_0 — Data to program into memory mode register 16 for chip select 0. Reset Source: ctl_amod_g_rst_n
0x24D0 emif_ctlcfg_DENALI_PI_308
  [31:24] PI_MR40_DATA_0 — Data to program into memory mode register 40 for chip select 0. Reset Source: ctl_amod_g_rst_n
  [16:0] PI_MR32_DATA_0 — Data to program into memory mode register 32 for chip select 0. Reset Source: ctl_amod_g_rst_n
0x24D4 emif_ctlcfg_DENALI_PI_309
  [31:24] PI_MR17_DATA_1 — Data to program into memory mode register 17 for chip select 1. Reset Source: ctl_amod_g_rst_n
  [23:16] PI_MR16_DATA_1 — Data to program into memory mode register 16 for chip select 1. Reset Source: ctl_amod_g_rst_n
  [15:8] PI_MR15_DATA_1 — Data to program into memory mode register 15 for chip select 1. Reset Source: ctl_amod_g_rst_n
  [7:0] PI_MR13_DATA_1 — Data to program into memory mode register 13 for chip select 1. Reset Source: ctl_amod_g_rst_n
0x24D8 emif_ctlcfg_DENALI_PI_310
  [24:8] PI_MR32_DATA_1 — Data to program into memory mode register 32 for chip select 1. Reset Source: ctl_amod_g_rst_n
  [7:0] PI_MR20_DATA_1 — Data to program into memory mode register 20 for chip select 1. Reset Source: ctl_amod_g_rst_n
0x24DC emif_ctlcfg_DENALI_PI_311
  [31:24] PI_MR16_DATA_2 — Data to program into memory mode register 16 for chip select 2. Reset Source: ctl_amod_g_rst_n
  [23:16] PI_MR15_DATA_2 — Data to program into memory mode register 15 for chip select 2. Reset Source: ctl_amod_g_rst_n
  [15:8] PI_MR13_DATA_2 — Data to program into memory mode register 13 for chip select 2. Reset Source: ctl_amod_g_rst_n
  [7:0] PI_MR40_DATA_1 — Data to program into memory mode register 40 for chip select 1. Reset Source: ctl_amod_g_rst_n
0x24E0 emif_ctlcfg_DENALI_PI_312
  [15:8] PI_MR20_DATA_2 — Data to program into memory mode register 20 for chip select 2. Reset Source: ctl_amod_g_rst_n
  [7:0] PI_MR17_DATA_2 — Data to program into memory mode register 17 for chip select 2. Reset Source: ctl_amod_g_rst_n
0x24E4 emif_ctlcfg_DENALI_PI_313
  [31:24] PI_MR40_DATA_2 — Data to program into memory mode register 40 for chip select 2. Reset Source: ctl_amod_g_rst_n
  [16:0] PI_MR32_DATA_2 — Data to program into memory mode register 32 for chip select 2. Reset Source: ctl_amod_g_rst_n
0x24E8 emif_ctlcfg_DENALI_PI_314
  [31:24] PI_MR17_DATA_3 — Data to program into memory mode register 17 for chip select 3. Reset Source: ctl_amod_g_rst_n
  [23:16] PI_MR16_DATA_3 — Data to program into memory mode register 16 for chip select 3. Reset Source: ctl_amod_g_rst_n
  [15:8] PI_MR15_DATA_3 — Data to program into memory mode register 15 for chip select 3. Reset Source: ctl_amod_g_rst_n
  [7:0] PI_MR13_DATA_3 — Data to program into memory mode register 13 for chip select 3. Reset Source: ctl_amod_g_rst_n
0x24EC emif_ctlcfg_DENALI_PI_315
  [24:8] PI_MR32_DATA_3 — Data to program into memory mode register 32 for chip select 3. Reset Source: ctl_amod_g_rst_n
  [7:0] PI_MR20_DATA_3 — Data to program into memory mode register 20 for chip select 3. Reset Source: ctl_amod_g_rst_n
0x24F0 emif_ctlcfg_DENALI_PI_316
  [28:24] PI_CKE_MUX_2 — Command pin CKE_2 mux selector Reset Source: ctl_amod_g_rst_n
  [20:16] PI_CKE_MUX_1 — Command pin CKE_1 mux selector Reset Source: ctl_amod_g_rst_n
  [12:8] PI_CKE_MUX_0 — Command pin CKE_0 mux selector Reset Source: ctl_amod_g_rst_n
  [7:0] PI_MR40_DATA_3 — Data to program into memory mode register 40 for chip select 3. Reset Source: ctl_amod_g_rst_n
0x24F4 emif_ctlcfg_DENALI_PI_317
  [28:24] PI_CS_MUX_2 — Command pin CS_2 mux selector Reset Source: ctl_amod_g_rst_n
  [20:16] PI_CS_MUX_1 — Command pin CS_1 mux selector Reset Source: ctl_amod_g_rst_n
  [12:8] PI_CS_MUX_0 — Command pin CS_0 mux selector Reset Source: ctl_amod_g_rst_n
  [4:0] PI_CKE_MUX_3 — Command pin CKE_3 mux selector Reset Source: ctl_amod_g_rst_n
0x24F8 emif_ctlcfg_DENALI_PI_318
  [28:24] PI_ODT_MUX_2 — Command pin ODT_2 mux selector Reset Source: ctl_amod_g_rst_n
  [20:16] PI_ODT_MUX_1 — Command pin ODT_1 mux selector Reset Source: ctl_amod_g_rst_n
  [12:8] PI_ODT_MUX_0 — Command pin ODT_0 mux selector Reset Source: ctl_amod_g_rst_n
  [4:0] PI_CS_MUX_3 — Command pin CS_3 mux selector Reset Source: ctl_amod_g_rst_n
0x24FC emif_ctlcfg_DENALI_PI_319
  [28:24] PI_RESET_N_MUX_2 — Command pin RESET_N_2 mux selector Reset Source: ctl_amod_g_rst_n
  [20:16] PI_RESET_N_MUX_1 — Command pin RESET_N_1 mux selector Reset Source: ctl_amod_g_rst_n
  [12:8] PI_RESET_N_MUX_0 — Command pin RESET_N_0 mux selector Reset Source: ctl_amod_g_rst_n
  [4:0] PI_ODT_MUX_3 — Command pin ODT_3 mux selector Reset Source: ctl_amod_g_rst_n
0x2500 emif_ctlcfg_DENALI_PI_320
  [24:8] PI_MRSINGLE_DATA_0 — Data to program into memory mode register single write to chip select 0. Reset Source: ctl_amod_g_rst_n
  [4:0] PI_RESET_N_MUX_3 — Command pin RESET_N_3 mux selector Reset Source: ctl_amod_g_rst_n
0x2504 emif_ctlcfg_DENALI_PI_321
  [16:0] PI_MRSINGLE_DATA_1 — Data to program into memory mode register single write to chip select 1. Reset Source: ctl_amod_g_rst_n
0x2508 emif_ctlcfg_DENALI_PI_322
  [16:0] PI_MRSINGLE_DATA_2 — Data to program into memory mode register single write to chip select 2. Reset Source: ctl_amod_g_rst_n
0x250C emif_ctlcfg_DENALI_PI_323 reset 0x1000000
  [27:24] PI_ZQ_CAL_START_MAP_0 — Defines which chip select[s] will receive ZQ calibration start commands simultaneously on iteration 0 of the ZQ START initialization and periodic command sequences. Clear to all zeros for no ZQ START commands. Reset Source: ctl_amod_g_rst_n
  [16:0] PI_MRSINGLE_DATA_3 — Data to program into memory mode register single write to chip select 3. Reset Source: ctl_amod_g_rst_n
